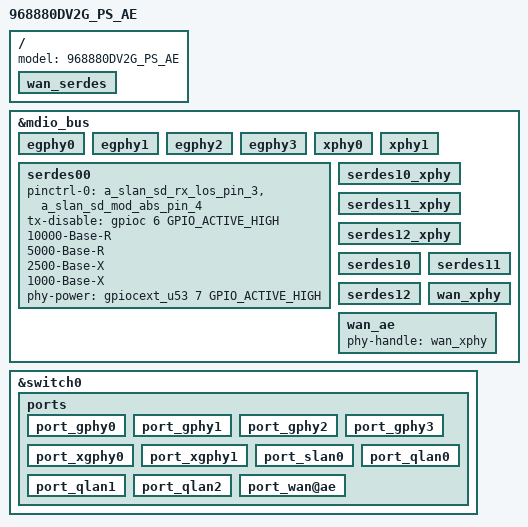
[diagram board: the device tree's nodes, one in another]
#include "inc/968880DV2G_PS.dtsi"

/ {
    model = "968880DV2G_PS_AE";

    wan_serdes {
        status = "okay";
    };
};

&mdio_bus {
    egphy0 {
        status = "okay";
    };
    egphy1 {
        status = "okay";
    };
    egphy2 {
        status = "okay";
    };
    egphy3 {
        status = "okay";
    };
    xphy0 {
        status = "okay";
    };
    xphy1 {
        status = "okay";
    };
    serdes00 {
        pinctrl-names = "default";
        pinctrl-0 = <&a_slan_sd_rx_los_pin_3 &a_slan_sd_mod_abs_pin_4>;
        tx-disable = <&gpioc 6 GPIO_ACTIVE_HIGH>;
        10000-Base-R;
        5000-Base-R;
        2500-Base-X;
        1000-Base-X;
        phy-power = <&gpiocext_u53 7 GPIO_ACTIVE_HIGH>; /* SLAN SFP power */
        status = "okay";
    };
    serdes10_xphy {
        status = "okay";
    };
    serdes11_xphy {
        status = "okay";
    };
    serdes12_xphy {
        status = "okay";
    };
    serdes10 {
        status = "okay";
    };
    serdes11 {
        status = "okay";
    };
    serdes12 {
        status = "okay";
    };
    wan_xphy {
        status = "okay";
    };
    wan_ae {
        phy-handle = <&wan_xphy>;
        status = "okay";
    };
};

&switch0 {
    ports {
        port_gphy0 {
            status = "okay";
        };
        port_gphy1 {
            status = "okay";
        };
        port_gphy2 {
            status = "okay";
        };
        port_gphy3 {
            status = "okay";
        };
        port_xgphy0 {
            status = "okay";
        };
        port_xgphy1 {
            status = "okay";
        };
        port_slan0 {
            status = "okay";
        };
        port_qlan0 {
            status = "okay";
        };
        port_qlan1 {
            status = "okay";
        };
        port_qlan2 {
            status = "okay";
        };
        port_wan@ae {
            status = "okay";
        };
    };
};
